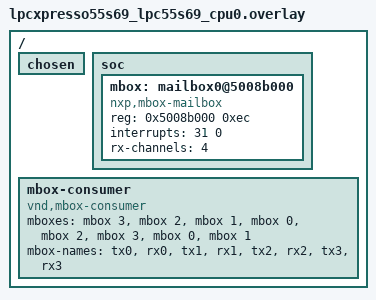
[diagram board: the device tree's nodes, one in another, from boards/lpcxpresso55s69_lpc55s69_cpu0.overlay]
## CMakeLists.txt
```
# Copyright 2024-2025 NXP
#
# SPDX-License-Identifier: Apache-2.0
#

cmake_minimum_required(VERSION 3.28.0)

find_package(Zephyr REQUIRED HINTS $ENV{ZEPHYR_BASE})

set(REMOTE_ZEPHYR_DIR ${CMAKE_CURRENT_BINARY_DIR}/../remote/zephyr)

project(mbox_data_ipc)

enable_language(C ASM)

if(CONFIG_INCLUDE_REMOTE_DIR)
  target_include_directories(zephyr_interface
    INTERFACE ${REMOTE_ZEPHYR_DIR}/include/public)
endif()

target_sources(app PRIVATE src/main.c)
```

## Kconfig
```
# Copyright 2024-2025 NXP
#
# SPDX-License-Identifier: Apache-2.0

source "Kconfig.zephyr"

config INCLUDE_REMOTE_DIR
	bool "Include remote core header directory"
	help
	  Include remote build header files. Can be used if primary image
	  needs to be aware of size or base address of secondary image

config TEST_SINGLE_CPU
	bool "Enable mailbox test on single CPU core"
	help
	  Perform a test in which a CPU uses a mailbox channel to exchange messages with itself

config CHANNELS_TO_TEST
	int "Number of mbox TX/RX channel pairs to test"
	default 4
	help
	  The number of TX/RX channel pairs that should be exercise by
	  this test. This should match the number of pairs set in the
	  devicetree.
```

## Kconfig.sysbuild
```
# Copyright 2024 NXP
#
# SPDX-License-Identifier: Apache-2.0

source "share/sysbuild/Kconfig"

config REMOTE_BOARD
string
	default "mimxrt1170_evkb/mimxrt1176/cm4" if $(BOARD) = "mimxrt1170_evkb"
	default "mimxrt1170_evk/mimxrt1176/cm4" if $(BOARD) = "mimxrt1170_evk"
	default "mimxrt1160_evk/mimxrt1166/cm4" if $(BOARD) = "mimxrt1160_evk"
	default "lpcxpresso55s69/lpc55s69/cpu1" if $(BOARD) = "lpcxpresso55s69"
	default "mimxrt1180_evk/mimxrt1189/cm7" if $(BOARD) = "mimxrt1180_evk"
	default "frdm_imxrt1186/mimxrt1186/cm7" if $(BOARD) = "frdm_imxrt1186"
	default "ek_ra8p1/r7ka8p1kflcac/cm33" if $(BOARD) = "ek_ra8p1"
	default "ek_ra8d2/r7ka8d2kflcac/cm33" if $(BOARD) = "ek_ra8d2"
	default "ek_ra8m2/r7ka8m2jflcac/cm33" if $(BOARD) = "ek_ra8m2"
	default "ek_ra8t2/r7ka8t2lflcac/cm33" if $(BOARD) = "ek_ra8t2"
	default "mck_ra8t2/r7ka8t2lflcac/cm33" if $(BOARD) = "mck_ra8t2"
	default "max78002evkit/max78002/rv32" if $(BOARD) = "max78002evkit"
	default "max32690evkit/max32690/rv32" if $(BOARD) = "max32690evkit"
	default "max32655evkit/max32655/rv32" if $(BOARD) = "max32655evkit"
```

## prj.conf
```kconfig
CONFIG_PRINTK=y
CONFIG_MBOX=y
CONFIG_ZTEST=y
```

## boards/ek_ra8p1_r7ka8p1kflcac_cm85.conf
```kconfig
# Copyright (c) 2025 Renesas Electronics Corporation
# SPDX-License-Identifier: Apache-2.0

CONFIG_SOC_RA_ENABLE_START_SECOND_CORE=y
```

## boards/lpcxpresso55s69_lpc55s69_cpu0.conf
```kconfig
CONFIG_SECOND_CORE_MCUX=y
CONFIG_MBOX_NXP_MAILBOX=y
CONFIG_BUILD_OUTPUT_HEX=y
```

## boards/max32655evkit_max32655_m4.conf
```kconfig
# Copyright (c) 2025 Analog Devices, Inc.
# SPDX-License-Identifier: Apache-2.0

CONFIG_MAX32_SECONDARY_RV32=y
CONFIG_MAX32_SECONDARY_RV32_STARTUP_DELAY=15000000
CONFIG_BOOT_DELAY=300

CONFIG_CHANNELS_TO_TEST=1
```

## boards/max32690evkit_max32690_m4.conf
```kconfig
# Copyright (c) 2025 Analog Devices, Inc.
# SPDX-License-Identifier: Apache-2.0

CONFIG_MAX32_SECONDARY_RV32=y
CONFIG_MAX32_SECONDARY_RV32_STARTUP_DELAY=30000000
CONFIG_BOOT_DELAY=300

CONFIG_CHANNELS_TO_TEST=1
```

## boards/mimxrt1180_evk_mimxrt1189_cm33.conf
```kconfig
CONFIG_SECOND_CORE_MCUX=y
CONFIG_INCLUDE_REMOTE_DIR=y
```

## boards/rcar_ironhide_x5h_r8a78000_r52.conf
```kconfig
# Nothing here
```

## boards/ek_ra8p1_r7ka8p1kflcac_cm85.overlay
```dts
/*
 * Copyright (c) 2025 Renesas Electronics Corporation
 * SPDX-License-Identifier: Apache-2.0
 */

/ {
	mbox-consumer {
		compatible = "vnd,mbox-consumer";
		mboxes = <&mbox0 0>, <&mbox0 0>, <&mbox1 0>, <&mbox1 0>,
			 <&mbox1 0>, <&mbox1 0>, <&mbox0 0>, <&mbox0 0>;
		mbox-names = "tx0", "rx0", "tx1", "rx1", "tx2", "rx2", "tx3",
			     "rx3";
	};
};

&mbox0 {
	interrupts = <94 1>;
	status = "okay";
};

&mbox1 {
	interrupts = <95 1>;
	status = "okay";
};
```

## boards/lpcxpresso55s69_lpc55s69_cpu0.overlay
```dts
/*
 * Copyright 2024 NXP
 *
 * SPDX-License-Identifier: Apache-2.0
 */

/ {
	chosen {
		/* Delete ipc chosen property where old IPM mailbox driver below is
		 * configured.
		 */
		/delete-property/ zephyr,ipc;
	};

	soc {
		/* Delete IPM Driver node nxp,lpc-mailbox */
		/delete-node/ mailbox@8b000;

		/* Attach MBOX driver to Mailbox Unit */
		mbox: mailbox0@5008b000 {
			compatible = "nxp,mbox-mailbox";
			reg = <0x5008b000 0xec>;
			interrupts = <31 0>;
			rx-channels = <4>;
			#mbox-cells = <1>;
			status = "okay";
		};
	};

	mbox-consumer {
		compatible = "vnd,mbox-consumer";
		mboxes = <&mbox 3>, <&mbox 2>, <&mbox 1>, <&mbox 0>, <&mbox 2>,
			 <&mbox 3>, <&mbox 0>, <&mbox 1>;
		mbox-names = "tx0", "rx0", "tx1", "rx1", "tx2", "rx2", "tx3",
			     "rx3";
	};
};
```

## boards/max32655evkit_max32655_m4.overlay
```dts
/*
 * Copyright 2025 Analog Devices, Inc
 *
 * SPDX-License-Identifier: Apache-2.0
 */

&mbox {
	status = "okay";
	msg-payloads;
};

/ {
	mbox-consumer {
		compatible = "vnd,mbox-consumer";
		mboxes = <&mbox 0>, <&mbox 0>;
		mbox-names = "rx0", "tx0";
	};
};
```

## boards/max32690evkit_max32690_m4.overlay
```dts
/*
 * Copyright 2025 Analog Devices, Inc
 *
 * SPDX-License-Identifier: Apache-2.0
 */

&mbox {
	msg-payloads;
	status = "okay";
};

/ {
	mbox-consumer {
		compatible = "vnd,mbox-consumer";
		mboxes = <&mbox 0>, <&mbox 0>;
		mbox-names = "rx0", "tx0";
	};
};
```

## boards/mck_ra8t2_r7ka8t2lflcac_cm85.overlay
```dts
/*
 * Copyright (c) 2026 Renesas Electronics Corporation
 * SPDX-License-Identifier: Apache-2.0
 */

/ {
	mbox-consumer {
		compatible = "vnd,mbox-consumer";
		mboxes = <&mbox0 0>, <&mbox0 0>, <&mbox1 0>, <&mbox1 0>,
			 <&mbox1 0>, <&mbox1 0>, <&mbox0 0>, <&mbox0 0>;
		mbox-names = "tx0", "rx0", "tx1", "rx1", "tx2", "rx2", "tx3",
			     "rx3";
	};
};

&mbox0 {
	interrupts = <94 1>;
	status = "okay";
};

&mbox1 {
	interrupts = <95 1>;
	status = "okay";
};
```

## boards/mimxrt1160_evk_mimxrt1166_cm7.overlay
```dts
/*
 * Copyright 2024 NXP
 *
 * SPDX-License-Identifier: Apache-2.0
 */

/ {
	chosen {
		/* Delete ipc chosen property where old IPM mailbox driver bellow is
		 * configured.
		 */
		/delete-property/ zephyr,ipc;
	};

	soc {
		/* Delete IPM Driver node nxp,imx-mu */
		/delete-node/ mailbox@40c48000;

		/* Attach MBOX driver to MU Unit */
		mbox:mbox@40c48000 {
			compatible = "nxp,mbox-imx-mu";
			reg = <0x40c48000 0x4000>;
			interrupts = <118 0>;
			rx-channels = <4>;
			#mbox-cells = <1>;
			status = "okay";
		};
	};

	mbox-consumer {
		compatible = "vnd,mbox-consumer";
		mboxes = <&mbox 3>, <&mbox 2>, <&mbox 1>, <&mbox 0>, <&mbox 2>,
			 <&mbox 3>, <&mbox 0>, <&mbox 1>;
		mbox-names = "tx0", "rx0", "tx1", "rx1", "tx2", "rx2", "tx3",
			     "rx3";
	};
};
```

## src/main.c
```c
/*
 * Copyright 2024-2025 NXP
 *
 * SPDX-License-Identifier: Apache-2.0
 */

#include <stdio.h>
#include <stdlib.h>
#include <string.h>
#include <zephyr/kernel.h>
#include <zephyr/drivers/mbox.h>

#include <zephyr/ztest.h>

static K_SEM_DEFINE(g_mbox_data_rx_sem, 0, 1);

static uint64_t g_mbox_received_data;
static uint64_t g_mbox_expected_data;
static uint32_t g_mbox_received_channel;
static uint32_t g_mbox_expected_channel;

static bool g_received_size_error;
static size_t g_received_size;
static int g_max_transfer_size_bytes;

#define TX_CHANNEL_INDEX 0
#define RX_CHANNEL_INDEX 1

#if DT_HAS_COMPAT_STATUS_OKAY(zephyr_mbox_consumer)
#define MBOX_CONSUMER_NODE DT_COMPAT_GET_ANY_STATUS_OKAY(zephyr_mbox_consumer)
#elif DT_HAS_COMPAT_STATUS_OKAY(vnd_mbox_consumer)
#define MBOX_CONSUMER_NODE DT_COMPAT_GET_ANY_STATUS_OKAY(vnd_mbox_consumer)
#else
#error "No zephyr,mbox-consumer or vnd,mbox-consumer node in the devicetree"
#endif

BUILD_ASSERT(DT_PROP_LEN(MBOX_CONSUMER_NODE, mboxes) % 2 == 0,
	     "mboxes must contain tx/rx channel pairs");

#define CHANNELS_TO_TEST (DT_PROP_LEN(MBOX_CONSUMER_NODE, mboxes) / 2)

#if CHANNELS_TO_TEST > 4
#error "The test suite covers at most 4 tx/rx channel pairs"
#endif

/* On loopback platforms sent data comes back unmodified instead of being
 * incremented by a remote core.
 */
#define TEST_LOOPBACK DT_PROP_OR(MBOX_CONSUMER_NODE, loopback, 0)

#define CHANNEL_ENTRY(_i)                                                                          \
	{                                                                                          \
		MBOX_DT_SPEC_GET(MBOX_CONSUMER_NODE, CONCAT(tx, _i)),                              \
		MBOX_DT_SPEC_GET(MBOX_CONSUMER_NODE, CONCAT(rx, _i)),                              \
	}

static const struct mbox_dt_spec channels[CHANNELS_TO_TEST][2] = {
	CHANNEL_ENTRY(0),
#if CHANNELS_TO_TEST >= 2
	CHANNEL_ENTRY(1),
#endif
#if CHANNELS_TO_TEST >= 3
	CHANNEL_ENTRY(2),
#endif
#if CHANNELS_TO_TEST >= 4
	CHANNEL_ENTRY(3),
#endif
};

static uint32_t current_channel_index;

static void callback(const struct device *dev, uint32_t channel, void *user_data,
		     struct mbox_msg *data)
{
	/* Handle the case if received invalid size */
	if (data->size > sizeof(g_mbox_received_data)) {
		g_received_size_error = true;
		g_received_size = data->size;
	} else {
		memcpy(&g_mbox_received_data, data->data, data->size);
	}

	g_mbox_received_channel = channel;

	k_sem_give(&g_mbox_data_rx_sem);
}

static void mbox_data_tests_before(void *f)
{
	zassert_false(current_channel_index >= CHANNELS_TO_TEST,
		      "Channel to test is out of range");

	const struct mbox_dt_spec *tx_channel = &channels[current_channel_index][TX_CHANNEL_INDEX];
	const struct mbox_dt_spec *rx_channel = &channels[current_channel_index][RX_CHANNEL_INDEX];
	int ret_val = 0;

	g_max_transfer_size_bytes = mbox_mtu_get_dt(tx_channel);
	/* Test currently supports only transfer size up to 8 bytes */
	if ((g_max_transfer_size_bytes < 0) || (g_max_transfer_size_bytes > 8)) {
		printk("mbox_mtu_get() error\n");
		zassert_false(1, "mbox invalid maximum transfer unit: %d",
			      g_max_transfer_size_bytes);
	}

	ret_val = mbox_register_callback_dt(rx_channel, callback, NULL);
	zassert_false(ret_val != 0, "mbox failed to register callback. ret_val: %d", ret_val);

	ret_val = mbox_set_enabled_dt(rx_channel, 1);
	zassert_false(ret_val != 0, "mbox failed to enable mbox. ret_val: %d", ret_val);
}

static void mbox_data_tests_after(void *f)
{
	zassert_false(current_channel_index >= CHANNELS_TO_TEST,
		      "Channel to test is out of range");

	const struct mbox_dt_spec *rx_channel = &channels[current_channel_index][RX_CHANNEL_INDEX];

	/* Disable channel after test end */
	int ret_val = mbox_set_enabled_dt(rx_channel, 0);

	zassert_false(ret_val != 0, "mbox failed to disable mbox. ret_val: %d", ret_val);

	/* Increment current channel index to its prepared for next test */
	current_channel_index++;
}

static void mbox_test(const uint64_t data)
{
	struct mbox_msg msg = {0};
	uint64_t test_data = data;
	int test_count = 0;
	int ret_val = 0;

	while (test_count < 100) {
		const struct mbox_dt_spec *tx_channel =
			&channels[current_channel_index][TX_CHANNEL_INDEX];

		/* Main core prepare test data */
		msg.data = &test_data;
		msg.size = g_max_transfer_size_bytes;

		/* Main core send test data */
		ret_val = mbox_send_dt(tx_channel, &msg);
		zassert_false(ret_val < 0, "mbox failed to send. ret_val: %d", ret_val);

		/*
		 * Determine expected received data based on the configured Maximum
		 * Transfer Unit (MTU). Supported MTU sizes are 1-8 bytes.
		 * On loopback channels the received data should match the sent
		 * data. Otherwise, it is expected to be incremented by one.
		 */
		g_mbox_expected_data = test_data & GENMASK64((g_max_transfer_size_bytes * 8) - 1,
							   0); /* Mask data to MTU size */
		if (!TEST_LOOPBACK) {
			g_mbox_expected_data++;
		}

		k_sem_take(&g_mbox_data_rx_sem, K_FOREVER);

		if (g_received_size_error) {
			zassert_false(1, "mbox received invalid size in callback: %zd",
				      g_received_size);
		}

		test_data = g_mbox_received_data;

		/* Main core check received data */
		zassert_equal(g_mbox_expected_data, test_data,
			      "Received test_data does not match!: Expected: %08llX, Got: %08llX",
			      g_mbox_expected_data, test_data);

		/* Expect reception of data on current RX channel */
		g_mbox_expected_channel =
			channels[current_channel_index][RX_CHANNEL_INDEX].channel_id;
		zassert_equal(g_mbox_expected_channel, g_mbox_received_channel,
			      "Received channel does not match!: Expected: %d, Got: %d",
			      g_mbox_expected_channel, g_mbox_received_channel);

		/* Increment for next send */
		test_data++;
		test_count++;
	}
}

/**
 * @brief MBOX Data transfer by ping pong for first set of channels
 *
 * This test verifies that the data transfer via MBOX.
 * Main core will transfer test data to remote core.
 * Remote core will increment data by one and transfer it back to Main core.
 * Main core will check that data it sent to remote core was incremented by one.
 * Main core will again increment test data by one, send it to remote core and repeat 100 times.
 */
ZTEST(mbox_data_tests, test_ping_pong_1)
{
	mbox_test(0xADADADAD);
}

#if CHANNELS_TO_TEST >= 2

/**
 * @brief MBOX Data transfer by ping pong for second set of channels
 *
 * Description same as for test_ping_pong_1
 *
 */
ZTEST(mbox_data_tests, test_ping_pong_2)
{
	mbox_test(0xDADADADA);
}

#endif

#if CHANNELS_TO_TEST >= 3

/**
 * @brief MBOX Data transfer by ping pong for third set of channels
 *
 * Description same as for test_ping_pong_1
 *
 */
ZTEST(mbox_data_tests, test_ping_pong_3)
{
	mbox_test(0xADADADAD);
}

#endif

#if CHANNELS_TO_TEST >= 4

/**
 * @brief MBOX Data transfer by ping pong for forth set of channels
 *
 * Description same as for test_ping_pong_1
 *
 */
ZTEST(mbox_data_tests, test_ping_pong_4)
{
	mbox_test(0xDADADADA);
}

#endif

ZTEST_SUITE(mbox_data_tests, NULL, NULL, mbox_data_tests_before, mbox_data_tests_after, NULL);
```
